# STM32U345 register map
File version: 1.0
CPU: CM33 r0p1, little endian, MPU, FPU, 4 interrupt priority bits
Registers are 32-bit, read-write, reset 0x0 unless marked. A register's access mark holds for its fields unless they carry their own. Offsets are from the block's base; [hi:lo] are bit positions; {n}, {i} and the like mark numbered series.

## DLYBQS1 — DLYB Address block
Base 0x420CF000
Same registers: DLYBQS1_S 0x520CF000
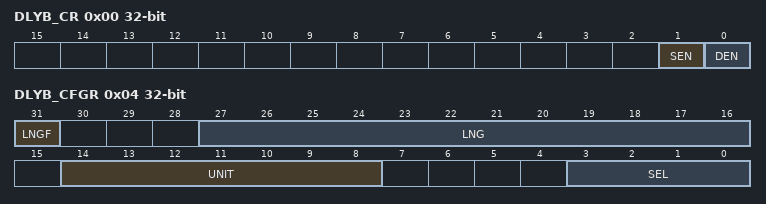
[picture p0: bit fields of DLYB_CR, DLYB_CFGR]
0x00 DLYB_CR — DLYB control register
  [1] SEN — 0: Sampler length and register access to UNIT[6:0] and SEL[3:0] disabled, output clock enabled. 1: Sampler length and register access to UNIT[6:0] and SEL[3:0] enabled, output clock disabled.
    0=Sampler length and register access to UNIT[6:0] and SEL[3:0] disabled, output clock enabled; 1=Sampler length and register access to UNIT[6:0] and SEL[3:0] enabled, output clock disabled
  [0] DEN — 0: DLYB disabled. 1: DLYB enabled.
    0=DLYB disabled; 1=DLYB enabled
0x04 DLYB_CFGR access per field — DLYB configuration register
  [31] LNGF ro — This flag indicates when the delay line length value contained in LNG[11:0] is valid after UNIT[6:0] bits changed. 0: Length value in LNG is not valid. 1: Length value in LNG is valid.
    0=Length value in LNG is not valid; 1=Length value in LNG is valid
  [27:16] LNG ro — These bits reflect the 12 unit delay values sampled at the rising edge of the input clock. The value is only valid when LNGF = 1.
  [14:8] UNIT rw — These bits can only be written when SEN = 1. Unit delay = initial delay + UNIT[6:0] x delay step
  [3:0] SEL rw — These bits can only be written when SEN = 1. Output clock phase = input clock + SEL[3:0] x unit delay

## GTZC1_MPCBB1 — GTZC1_MPCBB1 Address block
Base 0x40032C00
Same registers: GTZC1_MPCBB1_S 0x50032C00
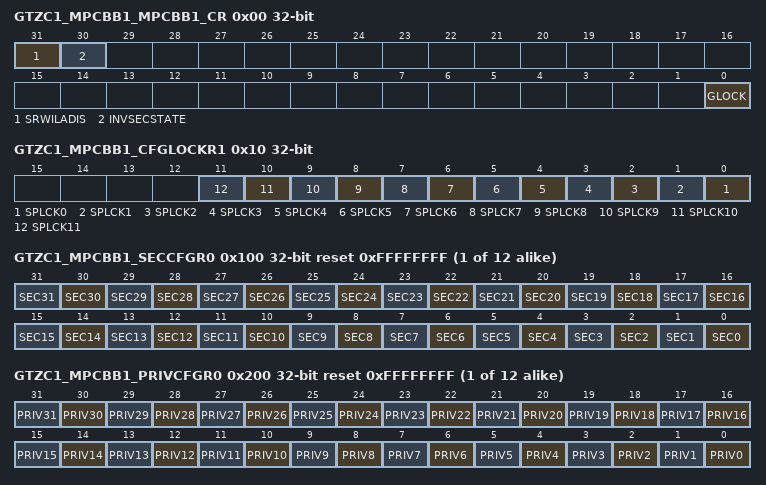
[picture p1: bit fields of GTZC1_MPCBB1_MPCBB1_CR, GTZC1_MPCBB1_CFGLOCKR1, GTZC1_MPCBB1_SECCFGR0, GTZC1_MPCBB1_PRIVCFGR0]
0x00 GTZC1_MPCBB1_MPCBB1_CR — Secure privileged access only.
  [31] SRWILADIS — secure read/write illegal access disable This bit disables the detection of an illegal access when a secure read/write transaction access a non-secure blocks of the block-based SRAM (secure fetch on non-secure block is always considered illegal).
    0=enabled, secure read/write access not allowed on non-secure SRAM block; 1=disabled, secure read/write access allowed on non-secure SRAM block
  [30] INVSECSTATE — SRAM1 clocks security state This bit is used to define the internal SRAMs clocks control in RCC as secure or not.
    0=SRAMs clocks are secure if a secure area exists in the MPCBB. It is non secure if there is no secure area.; 1=SRAMs clocks are non-secure even if a secure area exists in the MPCBB, and secure even if no secure block is set in the MPCBB
  [0] GLOCK — lock the control register of the MPCBB until next reset This bit is cleared by default and once set, it can not be reset until system reset.
    0=control register not locked; 1=control register locked
0x10 GTZC1_MPCBB1_CFGLOCKR1 — Secure privileged access only.
  [n] SPLCK{n} (n=0..11) — Security/privilege configuration lock for super-block {n} This bit is set by software and can be cleared only by system reset. Note: The maximum number of super blocks depends on the device.
    0=GTZC1_MPCBB1_SECCFGR{n} and GTZC1_MPCBB1_PRIVCFGR{n} can be written; 1=Writes to GTZC1_MPCBB1_SECCFGR{n} and GTZC1_MPCBB1_PRIVCFGR{n} are ignored
{0x100+4i} GTZC1_MPCBB1_SECCFGR{i} reset 0xFFFFFFFF (i=0..11) — The given reset value is valid when TZEN=1. The reset value is 0x00000000 when TZEN=0. Write access to this register is secure only. Any read is allowed. The maximum number of super blocks depends on the device
  [n] SEC{n} (n=0..31) — Security configuration for block {n} Unprivileged write to this bit is ignored if PRIV{n} bit is set in GTZC1_MPCBB1_PRIVCFGR{i}. Writes are ignored if SPLCK{i} bit is set in GTZC1_MPCBB1_CFGLOCKR1.
    0=Non-secure access only to block {n}, belonging to super-block {i}. Secure access is also allowed if the SRWILADIS bit is set in GTZC1_MPCBBz_CR.; 1=Secure access only to block {n}, belonging to super-block {i}
{0x200+4i} GTZC1_MPCBB1_PRIVCFGR{i} reset 0xFFFFFFFF (i=0..11) — The given reset value is valid when TZEN=1. The reset value is 0x00000000 when TZEN=0. Write access to this register is privileged only. Any read is allowed. The maximum number of super blocks depends on the device.
  [n] PRIV{n} (n=0..31) — Privileged configuration for block {n}, belonging to super-block {i} Non-secure write to this bit is ignored if SEC{n} bit is set in GTZC1_MPCBB1_SECCFGR{i}. Writes are ignored if SPLCK{i} bit is set in GTZC1_MPCBB1_CFGLOCKR1.
    0=Privileged and unprivileged access to block {n}, belonging to super-block {i}; 1=Only privileged access to block {n}, belonging to super-block {i}
